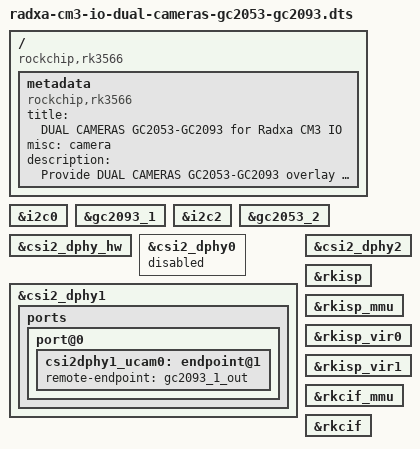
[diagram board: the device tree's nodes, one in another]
/dts-v1/;
/plugin/;

/ {
	compatible = "rockchip,rk3566";

	metadata {
		title = "DUAL CAMERAS GC2053-GC2093 for Radxa CM3 IO";
		compatible = "rockchip,rk3566";
		misc = "camera";
		description = "Provide DUAL CAMERAS GC2053-GC2093 overlay for Radxa CM3 IO";
	};

	fragment@0 {
		target = <&i2c0>;

		__overlay__ {
			status = "okay";
		};
	};

	fragment@1 {
		target = <&gc2093_1>;

		__overlay__ {
			status = "okay";
		};
	};

	fragment@2 {
		target = <&i2c2>;

		__overlay__ {
			status = "okay";
		};
	};

	fragment@3 {
		target = <&gc2053_2>;

		__overlay__ {
			status = "okay";
		};
	};

	fragment@4 {
		target = <&csi2_dphy_hw>;

		__overlay__ {
			status = "okay";
		};
	};

	fragment@5 {
		target = <&csi2_dphy0>;

		__overlay__ {
			status = "disabled";
		};
	};

	fragment@6 {
		target = <&csi2_dphy1>;

		__overlay__ {
			status = "okay";
			ports {
				port@0 {
					csi2dphy1_ucam0: endpoint@1 {
						remote-endpoint = <&gc2093_1_out>;
					};
				};
			};
		};
	};

	fragment@7 {
		target = <&csi2_dphy2>;

		__overlay__ {
			status = "okay";
		};
	};

	fragment@8 {
		target = <&rkisp>;

		__overlay__ {
			status = "okay";
		};
	};

	fragment@9 {
		target = <&rkisp_mmu>;

		__overlay__ {
			status = "okay";
		};
	};

	fragment@10 {
		target = <&rkisp_vir0>;

		__overlay__ {
			status = "okay";
		};
	};

	fragment@11 {
		target = <&rkisp_vir1>;

		__overlay__ {
			status = "okay";
		};
	};

	fragment@12 {
		target = <&rkcif_mmu>;

		__overlay__ {
			status = "okay";
		};
	};

	fragment@13 {
		target = <&rkcif>;

		__overlay__ {
			status = "okay";
		};
	};
};
